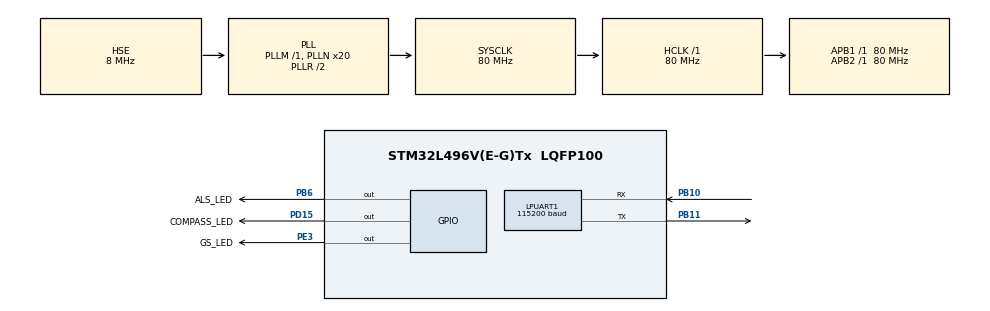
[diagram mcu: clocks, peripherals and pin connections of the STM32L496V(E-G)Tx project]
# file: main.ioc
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LPUART1.BaudRate=115200
LPUART1.WordLength=UART_WORDLENGTH_8B
Mcu.Family=STM32L4
Mcu.Name=STM32L496V(E-G)Tx
Mcu.Package=LQFP100
NVIC.PriorityGroup=NVIC_PRIORITYGROUP_4
PA13\ (JTMS/SWDIO).Mode=Serial_Wire
PA13\ (JTMS/SWDIO).Signal=SYS_JTMS-SWDIO
PA14\ (JTCK/SWCLK).Mode=Serial_Wire
PA14\ (JTCK/SWCLK).Signal=SYS_JTCK-SWCLK
PB10.Mode=Asynchronous
PB10.Signal=LPUART1_RX
PB11.Mode=Asynchronous
PB11.Signal=LPUART1_TX
PB6.GPIO_Label=ALS_LED
PB6.GPIO_Speed=GPIO_SPEED_FREQ_VERY_HIGH
PB6.Signal=GPIO_Output
PD15.GPIO_Label=COMPASS_LED
PD15.GPIO_Speed=GPIO_SPEED_FREQ_VERY_HIGH
PD15.Signal=GPIO_Output
PE3.GPIO_Label=GS_LED
PE3.GPIO_Speed=GPIO_SPEED_FREQ_VERY_HIGH
PE3.Signal=GPIO_Output
PH0-OSC_IN\ (PH0).Mode=HSE-External-Oscillator
PH0-OSC_IN\ (PH0).Signal=RCC_OSC_IN
PH1-OSC_OUT\ (PH1).Mode=HSE-External-Oscillator
PH1-OSC_OUT\ (PH1).Signal=RCC_OSC_OUT
ProjectManager.HeapSize=0x200
ProjectManager.StackSize=0x400
ProjectManager.TargetToolchain=MDK-ARM V5
RCC.ADCFreq_Value=48000000
RCC.AHBFreq_Value=80000000
RCC.APB1Freq_Value=80000000
RCC.APB1TimFreq_Value=80000000
RCC.APB2Freq_Value=80000000
RCC.APB2TimFreq_Value=80000000
RCC.CortexFreq_Value=80000000
RCC.HCLKFreq_Value=80000000
RCC.HSE_VALUE=8000000
RCC.HSI48_VALUE=48000000
RCC.HSI_VALUE=16000000
RCC.LSE_VALUE=32768
RCC.MSI_VALUE=4000000
RCC.PLLN=20
RCC.PLLSAI1N=12
RCC.PLLSourceVirtual=RCC_PLLSOURCE_HSE
RCC.SYSCLKFreq_VALUE=80000000
RCC.SYSCLKSource=RCC_SYSCLKSOURCE_PLLCLK
RCC.USBFreq_Value=48000000
RCC.VCOOutputFreq_Value=160000000
board=custom

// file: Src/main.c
/* USER CODE BEGIN Header */
/**
  ******************************************************************************
  * @file           : main.c
  * @brief          : Main program body
  ******************************************************************************
  * @attention
  *
  * <h2><center>&copy; Copyright (c) 2021 STMicroelectronics.
  * All rights reserved.</center></h2>
  *
  * This software component is licensed by ST under BSD 3-Clause license,
  * the "License"; You may not use this file except in compliance with the
  * License. You may obtain a copy of the License at:
  *                        opensource.org/licenses/BSD-3-Clause
  *
  ******************************************************************************
  */
/* USER CODE END Header */
#include "main.h"
#include "usart.h"
#include "gpio.h"

void SystemClock_Config(void);

int main(void)
{

  /* MCU Configuration--------------------------------------------------------*/

  /* Reset of all peripherals, Initializes the Flash interface and the Systick. */
  HAL_Init();

  /* Configure the system clock */
  SystemClock_Config();

  /* Initialize all configured peripherals */
  MX_GPIO_Init();
  MX_LPUART1_UART_Init();

  /* Infinite loop */
  while (1)
  {

    /* USER CODE BEGIN 3 */
		printf("Hello AliOS Things Developer Kit\n");
		HAL_GPIO_TogglePin(GS_LED_GPIO_Port,GS_LED_Pin);
		HAL_GPIO_TogglePin(COMPASS_LED_GPIO_Port,COMPASS_LED_Pin);
		HAL_GPIO_TogglePin(ALS_LED_GPIO_Port,ALS_LED_Pin);
		HAL_Delay(500);
  }
  /* USER CODE END 3 */
}

void SystemClock_Config(void)
{
  RCC_OscInitTypeDef RCC_OscInitStruct = {0};
  RCC_ClkInitTypeDef RCC_ClkInitStruct = {0};
  RCC_PeriphCLKInitTypeDef PeriphClkInit = {0};

  /** Initializes the RCC Oscillators according to the specified parameters
  * in the RCC_OscInitTypeDef structure.
  */
  RCC_OscInitStruct.OscillatorType = RCC_OSCILLATORTYPE_HSE;
  RCC_OscInitStruct.HSEState = RCC_HSE_ON;
  RCC_OscInitStruct.PLL.PLLState = RCC_PLL_ON;
  RCC_OscInitStruct.PLL.PLLSource = RCC_PLLSOURCE_HSE;
  RCC_OscInitStruct.PLL.PLLM = 1;
  RCC_OscInitStruct.PLL.PLLN = 20;
  RCC_OscInitStruct.PLL.PLLP = RCC_PLLP_DIV2;
  RCC_OscInitStruct.PLL.PLLQ = RCC_PLLQ_DIV2;
  RCC_OscInitStruct.PLL.PLLR = RCC_PLLR_DIV2;
  if (HAL_RCC_OscConfig(&RCC_OscInitStruct) != HAL_OK)
  {
    Error_Handler();
  }
  /** Initializes the CPU, AHB and APB buses clocks
  */
  RCC_ClkInitStruct.ClockType = RCC_CLOCKTYPE_HCLK|RCC_CLOCKTYPE_SYSCLK
                              |RCC_CLOCKTYPE_PCLK1|RCC_CLOCKTYPE_PCLK2;
  RCC_ClkInitStruct.SYSCLKSource = RCC_SYSCLKSOURCE_PLLCLK;
  RCC_ClkInitStruct.AHBCLKDivider = RCC_SYSCLK_DIV1;
  RCC_ClkInitStruct.APB1CLKDivider = RCC_HCLK_DIV1;
  RCC_ClkInitStruct.APB2CLKDivider = RCC_HCLK_DIV1;

  if (HAL_RCC_ClockConfig(&RCC_ClkInitStruct, FLASH_LATENCY_4) != HAL_OK)
  {
    Error_Handler();
  }
  PeriphClkInit.PeriphClockSelection = RCC_PERIPHCLK_LPUART1;
  PeriphClkInit.Lpuart1ClockSelection = RCC_LPUART1CLKSOURCE_PCLK1;
  if (HAL_RCCEx_PeriphCLKConfig(&PeriphClkInit) != HAL_OK)
  {
    Error_Handler();
  }
  /** Configure the main internal regulator output voltage
  */
  if (HAL_PWREx_ControlVoltageScaling(PWR_REGULATOR_VOLTAGE_SCALE1) != HAL_OK)
  {
    Error_Handler();
  }
}

void Error_Handler(void)
{
  __disable_irq();
  while (1)
  {
  }
}

/************************ (C) COPYRIGHT STMicroelectronics *****END OF FILE****/
